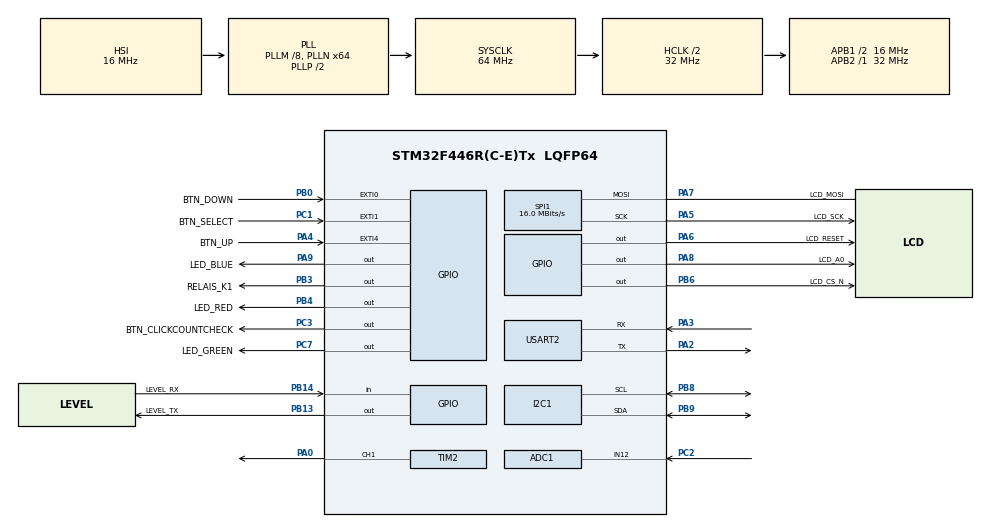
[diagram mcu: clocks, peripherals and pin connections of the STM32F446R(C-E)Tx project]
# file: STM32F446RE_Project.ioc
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ADC1.Channel-0\#ChannelRegularConversion=ADC_CHANNEL_12
ADC1.ClockPrescaler=ADC_CLOCK_SYNC_PCLK_DIV6
ADC1.ContinuousConvMode=ENABLE
ADC1.EOCSelection=ADC_EOC_SEQ_CONV
ADC1.NbrOfConversion=1
ADC1.NbrOfConversionFlag=1
ADC1.Rank-0\#ChannelRegularConversion=1
ADC1.SamplingTime-0\#ChannelRegularConversion=ADC_SAMPLETIME_480CYCLES
ADC1.ScanConvMode=ENABLE
ADC1.master=1
Mcu.Family=STM32F4
Mcu.Name=STM32F446R(C-E)Tx
Mcu.Package=LQFP64
NVIC.EXTI0_IRQn=true\:0\:0\:false\:false\:true\:true\:true\:true
NVIC.EXTI1_IRQn=true\:0\:0\:false\:false\:true\:true\:true\:true
NVIC.EXTI4_IRQn=true\:0\:0\:false\:false\:true\:true\:true\:true
NVIC.PriorityGroup=NVIC_PRIORITYGROUP_0
NVIC.TIM2_IRQn=true\:0\:0\:false\:false\:true\:true\:true\:true
PA0-WKUP.Signal=S_TIM2_CH1_ETR
PA2.Mode=Asynchronous
PA2.Signal=USART2_TX
PA3.Mode=Asynchronous
PA3.Signal=USART2_RX
PA4.GPIO_Label=BTN_UP
PA4.GPIO_PuPd=GPIO_PULLDOWN
PA4.Signal=GPXTI4
PA5.GPIO_Label=LCD_SCK
PA5.Mode=Simplex_Bidirectional_Master
PA5.Signal=SPI1_SCK
PA6.GPIO_Label=LCD_RESET
PA6.Signal=GPIO_Output
PA7.GPIO_Label=LCD_MOSI
PA7.Mode=Simplex_Bidirectional_Master
PA7.Signal=SPI1_MOSI
PA8.GPIO_Label=LCD_A0
PA8.Signal=GPIO_Output
PA9.GPIO_Label=LED_BLUE
PA9.Signal=GPIO_Output
PB0.GPIO_Label=BTN_DOWN
PB0.GPIO_PuPd=GPIO_PULLDOWN
PB0.Signal=GPXTI0
PB13.GPIO_Label=LEVEL_TX
PB13.Signal=GPIO_Output
PB14.GPIO_Label=LEVEL_RX
PB14.GPIO_PuPd=GPIO_PULLDOWN
PB14.Signal=GPIO_Input
PB3.GPIO_Label=RELAIS_K1
PB3.Signal=GPIO_Output
PB4.GPIO_Label=LED_RED
PB4.Signal=GPIO_Output
PB6.GPIO_Label=LCD_CS_N
PB6.Signal=GPIO_Output
PB8.Mode=I2C
PB8.Signal=I2C1_SCL
PB9.Mode=I2C
PB9.Signal=I2C1_SDA
PC1.GPIO_Label=BTN_SELECT
PC1.GPIO_PuPd=GPIO_PULLDOWN
PC1.Signal=GPXTI1
PC14-OSC32_IN.Mode=LSE-External-Oscillator
PC14-OSC32_IN.Signal=RCC_OSC32_IN
PC15-OSC32_OUT.Mode=LSE-External-Oscillator
PC15-OSC32_OUT.Signal=RCC_OSC32_OUT
PC2.Signal=ADCx_IN12
PC3.GPIO_Label=BTN_CLICKCOUNTCHECK
PC3.Signal=GPIO_Output
PC7.GPIO_Label=LED_GREEN
PC7.Signal=GPIO_Output
PH0-OSC_IN.Mode=HSE-External-Oscillator
PH0-OSC_IN.Signal=RCC_OSC_IN
PH1-OSC_OUT.Mode=HSE-External-Oscillator
PH1-OSC_OUT.Signal=RCC_OSC_OUT
ProjectManager.HeapSize=0x200
ProjectManager.StackSize=0x400
ProjectManager.TargetToolchain=STM32CubeIDE
RCC.48MHZClocksFreq_Value=84000000
RCC.AHBCLKDivider=RCC_SYSCLK_DIV2
RCC.AHBFreq_Value=32000000
RCC.APB1CLKDivider=RCC_HCLK_DIV2
RCC.APB1Freq_Value=16000000
RCC.APB1TimFreq_Value=32000000
RCC.APB2Freq_Value=32000000
RCC.APB2TimFreq_Value=32000000
RCC.CortexFreq_Value=32000000
RCC.FLatency-AdvancedSettings=FLASH_LATENCY_1
RCC.HCLKFreq_Value=32000000
RCC.HSE_VALUE=8000000
RCC.HSI_VALUE=16000000
RCC.PLLM=8
RCC.PLLN=64
RCC.SYSCLKFreq_VALUE=64000000
RCC.SYSCLKSource=RCC_SYSCLKSOURCE_PLLCLK
RCC.USBFreq_Value=64000000
RCC.VCOOutputFreq_Value=128000000
RTC.Date=1
RTC.Format=RTC_FORMAT_BIN
RTC.Hours=0
RTC.Minutes=0
RTC.Month=RTC_MONTH_JANUARY
RTC.WeekDay=RTC_WEEKDAY_MONDAY
RTC.Year=0
SH.ADCx_IN12.0=ADC1_IN12,IN12
SH.S_TIM2_CH1_ETR.0=TIM2_CH1,Output Compare1 CH1
SPI1.CalculateBaudRate=16.0 MBits/s
SPI1.Direction=SPI_DIRECTION_1LINE
SPI1.Mode=SPI_MODE_MASTER
SPI1.VirtualType=VM_MASTER
TIM2.Channel-Output\ Compare1\ CH1=TIM_CHANNEL_1
TIM2.Period=999
TIM2.Prescaler=31
USART2.VirtualMode=VM_ASYNC
VP_RTC_VS_RTC_Activate.Mode=RTC_Enabled
VP_RTC_VS_RTC_Calendar.Mode=RTC_Calendar
board=NUCLEO-F446RE

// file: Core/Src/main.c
/* USER CODE BEGIN Header */
/**
 ******************************************************************************
 * @file           : main.c
 * @brief          : Main program body
 ******************************************************************************
 * @attention
 *
 * Copyright (c) 2025 STMicroelectronics.
 * All rights reserved.
 *
 * This software is licensed under terms that can be found in the LICENSE file
 * in the root directory of this software component.
 * If no LICENSE file comes with this software, it is provided AS-IS.
 *
 ******************************************************************************
 */
/* USER CODE END Header */
#include "main.h"
#include "adc.h"
#include "i2c.h"
#include "rtc.h"
#include "spi.h"
#include "tim.h"
#include "usart.h"
#include "gpio.h"

/* USER CODE BEGIN Includes */
//#include "capsense.h"
//#include "stdio.h"
//#include "digTemp_KY_028.h"
//#include "lm75b.h"
//#include <lcd_driver.h>
//#include "stdbool.h"
#include "irrigation_state_machine.h"
#include "stdio.h"

/* USER CODE END Includes */

void SystemClock_Config(void);
/* USER CODE BEGIN PFP */
int _write(int file, char *ptr, int len);
/* USER CODE END PFP */

int main(void)
{

  /* MCU Configuration--------------------------------------------------------*/

  /* Reset of all peripherals, Initializes the Flash interface and the Systick. */
  HAL_Init();

  /* Configure the system clock */
  SystemClock_Config();

  /* Initialize all configured peripherals */
  MX_GPIO_Init();
  MX_USART2_UART_Init();
  MX_ADC1_Init();
  MX_I2C1_Init();
  MX_SPI1_Init();
  MX_RTC_Init();
  MX_TIM2_Init();
  /* USER CODE BEGIN 2 */
	Irrigation_Init();
//	if (HAL_RTCEx_BKUPRead(&hrtc, RTC_BKP_DR1) != 0x2345) {
//		// TODO: put "current" time & date here when flashing
//		// Example: 15:30:00 on 24 January 2025, Friday
//		RTC_SetTime(8, 00, 00);       // HH, MM, SS
//		RTC_SetDate(25, 12, 9, 2); // y,m,d,weekday
//	}

	RTC_SetTime(11, 30, 00);       // HH, MM, SS
	RTC_SetDate(25, 12, 9, 2); // y,m,d,weekday
	HAL_TIM_Base_Start_IT(&htim2);

  /* USER CODE END 2 */

  /* Infinite loop */
  /* USER CODE BEGIN WHILE */

	while (1) {

		Irrigation_Tick();

    /* USER CODE END WHILE */

	}
}

void SystemClock_Config(void)
{
  RCC_OscInitTypeDef RCC_OscInitStruct = {0};
  RCC_ClkInitTypeDef RCC_ClkInitStruct = {0};

  /** Configure the main internal regulator output voltage
  */
  __HAL_RCC_PWR_CLK_ENABLE();
  __HAL_PWR_VOLTAGESCALING_CONFIG(PWR_REGULATOR_VOLTAGE_SCALE3);

  /** Initializes the RCC Oscillators according to the specified parameters
  * in the RCC_OscInitTypeDef structure.
  */
  RCC_OscInitStruct.OscillatorType = RCC_OSCILLATORTYPE_HSI|RCC_OSCILLATORTYPE_LSI;
  RCC_OscInitStruct.LSEState = RCC_LSE_ON;
  RCC_OscInitStruct.HSIState = RCC_HSI_ON;
  RCC_OscInitStruct.HSICalibrationValue = RCC_HSICALIBRATION_DEFAULT;
  RCC_OscInitStruct.LSIState = RCC_LSI_ON;
  RCC_OscInitStruct.PLL.PLLState = RCC_PLL_ON;
  RCC_OscInitStruct.PLL.PLLSource = RCC_PLLSOURCE_HSI;
  RCC_OscInitStruct.PLL.PLLM = 8;
  RCC_OscInitStruct.PLL.PLLN = 64;
  RCC_OscInitStruct.PLL.PLLP = RCC_PLLP_DIV2;
  RCC_OscInitStruct.PLL.PLLQ = 2;
  RCC_OscInitStruct.PLL.PLLR = 2;
  if (HAL_RCC_OscConfig(&RCC_OscInitStruct) != HAL_OK)
  {
    Error_Handler();
  }

  /** Initializes the CPU, AHB and APB buses clocks
  */
  RCC_ClkInitStruct.ClockType = RCC_CLOCKTYPE_HCLK|RCC_CLOCKTYPE_SYSCLK
                              |RCC_CLOCKTYPE_PCLK1|RCC_CLOCKTYPE_PCLK2;
  RCC_ClkInitStruct.SYSCLKSource = RCC_SYSCLKSOURCE_PLLCLK;
  RCC_ClkInitStruct.AHBCLKDivider = RCC_SYSCLK_DIV2;
  RCC_ClkInitStruct.APB1CLKDivider = RCC_HCLK_DIV2;
  RCC_ClkInitStruct.APB2CLKDivider = RCC_HCLK_DIV1;

  if (HAL_RCC_ClockConfig(&RCC_ClkInitStruct, FLASH_LATENCY_1) != HAL_OK)
  {
    Error_Handler();
  }
}

/* USER CODE BEGIN 4 */
int _write(int file, char *ptr, int len) {
	// good version
	if (HAL_UART_Transmit(&huart2, (uint8_t*) ptr, len, HAL_MAX_DELAY)
			== HAL_OK)
		return len;
	else
		return -1;
}

/* USER CODE END 4 */

void Error_Handler(void)
{
	__disable_irq();
	while (1) {
	}
}
